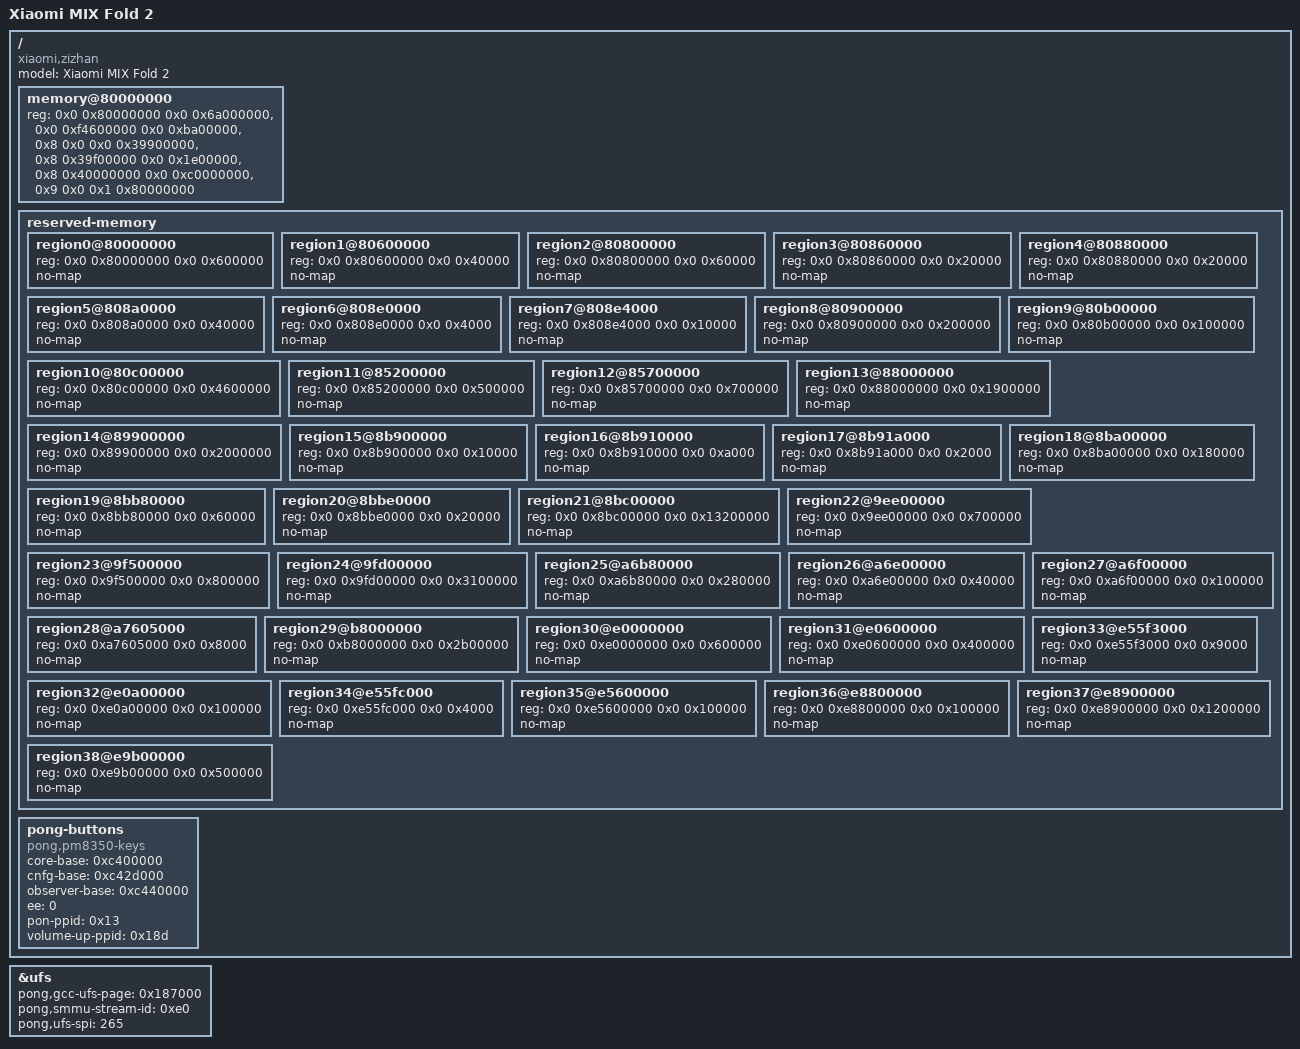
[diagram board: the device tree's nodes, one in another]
/dts-v1/;
/include/ "sm8475.dtsi"
// Generated from the zizhan live /sys/firmware/fdt (MIUI V14.0.15.0.TLRCNXM) by tools/zizhan/gen_reserved.py; layout follows UniXNU-pong dts/pong.dts (Nothing Phone (2)).
/ {
    model = "Xiaomi MIX Fold 2";
    compatible = "xiaomi,zizhan", "qcom,sm8475";
    memory@80000000 { device_type = "memory"; reg = <0x0 0x80000000 0x0 0x6a000000>, <0x0 0xf4600000 0x0 0xba00000>, <0x8 0x0 0x0 0x39900000>, <0x8 0x39f00000 0x0 0x1e00000>, <0x8 0x40000000 0x0 0xc0000000>, <0x9 0x0 0x1 0x80000000>; };
    reserved-memory {
        #address-cells = <2>;
        #size-cells = <2>;
        ranges;
        region0@80000000 { reg = <0x0 0x80000000 0x0 0x600000>; no-map; };
        region1@80600000 { reg = <0x0 0x80600000 0x0 0x40000>; no-map; };
        region2@80800000 { reg = <0x0 0x80800000 0x0 0x60000>; no-map; };
        region3@80860000 { reg = <0x0 0x80860000 0x0 0x20000>; no-map; };
        region4@80880000 { reg = <0x0 0x80880000 0x0 0x20000>; no-map; };
        region5@808a0000 { reg = <0x0 0x808a0000 0x0 0x40000>; no-map; };
        region6@808e0000 { reg = <0x0 0x808e0000 0x0 0x4000>; no-map; };
        region7@808e4000 { reg = <0x0 0x808e4000 0x0 0x10000>; no-map; };
        region8@80900000 { reg = <0x0 0x80900000 0x0 0x200000>; no-map; };
        region9@80b00000 { reg = <0x0 0x80b00000 0x0 0x100000>; no-map; };
        region10@80c00000 { reg = <0x0 0x80c00000 0x0 0x4600000>; no-map; };
        region11@85200000 { reg = <0x0 0x85200000 0x0 0x500000>; no-map; };
        region12@85700000 { reg = <0x0 0x85700000 0x0 0x700000>; no-map; };
        region13@88000000 { reg = <0x0 0x88000000 0x0 0x1900000>; no-map; };
        region14@89900000 { reg = <0x0 0x89900000 0x0 0x2000000>; no-map; };
        region15@8b900000 { reg = <0x0 0x8b900000 0x0 0x10000>; no-map; };
        region16@8b910000 { reg = <0x0 0x8b910000 0x0 0xa000>; no-map; };
        region17@8b91a000 { reg = <0x0 0x8b91a000 0x0 0x2000>; no-map; };
        region18@8ba00000 { reg = <0x0 0x8ba00000 0x0 0x180000>; no-map; };
        region19@8bb80000 { reg = <0x0 0x8bb80000 0x0 0x60000>; no-map; };
        region20@8bbe0000 { reg = <0x0 0x8bbe0000 0x0 0x20000>; no-map; };
        region21@8bc00000 { reg = <0x0 0x8bc00000 0x0 0x13200000>; no-map; };
        region22@9ee00000 { reg = <0x0 0x9ee00000 0x0 0x700000>; no-map; };
        region23@9f500000 { reg = <0x0 0x9f500000 0x0 0x800000>; no-map; };
        region24@9fd00000 { reg = <0x0 0x9fd00000 0x0 0x3100000>; no-map; };
        region25@a6b80000 { reg = <0x0 0xa6b80000 0x0 0x280000>; no-map; };
        region26@a6e00000 { reg = <0x0 0xa6e00000 0x0 0x40000>; no-map; };
        region27@a6f00000 { reg = <0x0 0xa6f00000 0x0 0x100000>; no-map; };
        region28@a7605000 { reg = <0x0 0xa7605000 0x0 0x8000>; no-map; };
        region29@b8000000 { reg = <0x0 0xb8000000 0x0 0x2b00000>; no-map; };
        region30@e0000000 { reg = <0x0 0xe0000000 0x0 0x600000>; no-map; };
        region31@e0600000 { reg = <0x0 0xe0600000 0x0 0x400000>; no-map; };
        region32@e0a00000 { reg = <0x0 0xe0a00000 0x0 0x100000>; no-map; };
        region33@e55f3000 { reg = <0x0 0xe55f3000 0x0 0x9000>; no-map; };
        region34@e55fc000 { reg = <0x0 0xe55fc000 0x0 0x4000>; no-map; };
        region35@e5600000 { reg = <0x0 0xe5600000 0x0 0x100000>; no-map; };
        region36@e8800000 { reg = <0x0 0xe8800000 0x0 0x100000>; no-map; };
        region37@e8900000 { reg = <0x0 0xe8900000 0x0 0x1200000>; no-map; };
        region38@e9b00000 { reg = <0x0 0xe9b00000 0x0 0x500000>; no-map; };
    };
    // Touch: zizhan uses two ST FTS controllers (SE4 SPI inner, SE19 SPI outer); no driver yet, node omitted.
    pong-buttons {
        compatible = "pong,pm8350-keys";
        core-base = /bits/ 64 <0xc400000>;
        cnfg-base = /bits/ 64 <0xc42d000>;
        observer-base = /bits/ 64 <0xc440000>;
        // Volume up is PM8350 GPIO6 on zizhan as on Pong (live DT gpio_keys/vol_up).
        ee = <0>; pon-ppid = <0x13>; volume-up-ppid = <0x18d>;
    };
};
&ufs { status = "okay"; pong,gcc-ufs-page = /bits/ 64 <0x187000>; pong,smmu-stream-id = <0xe0>; pong,ufs-spi = <265>; };
